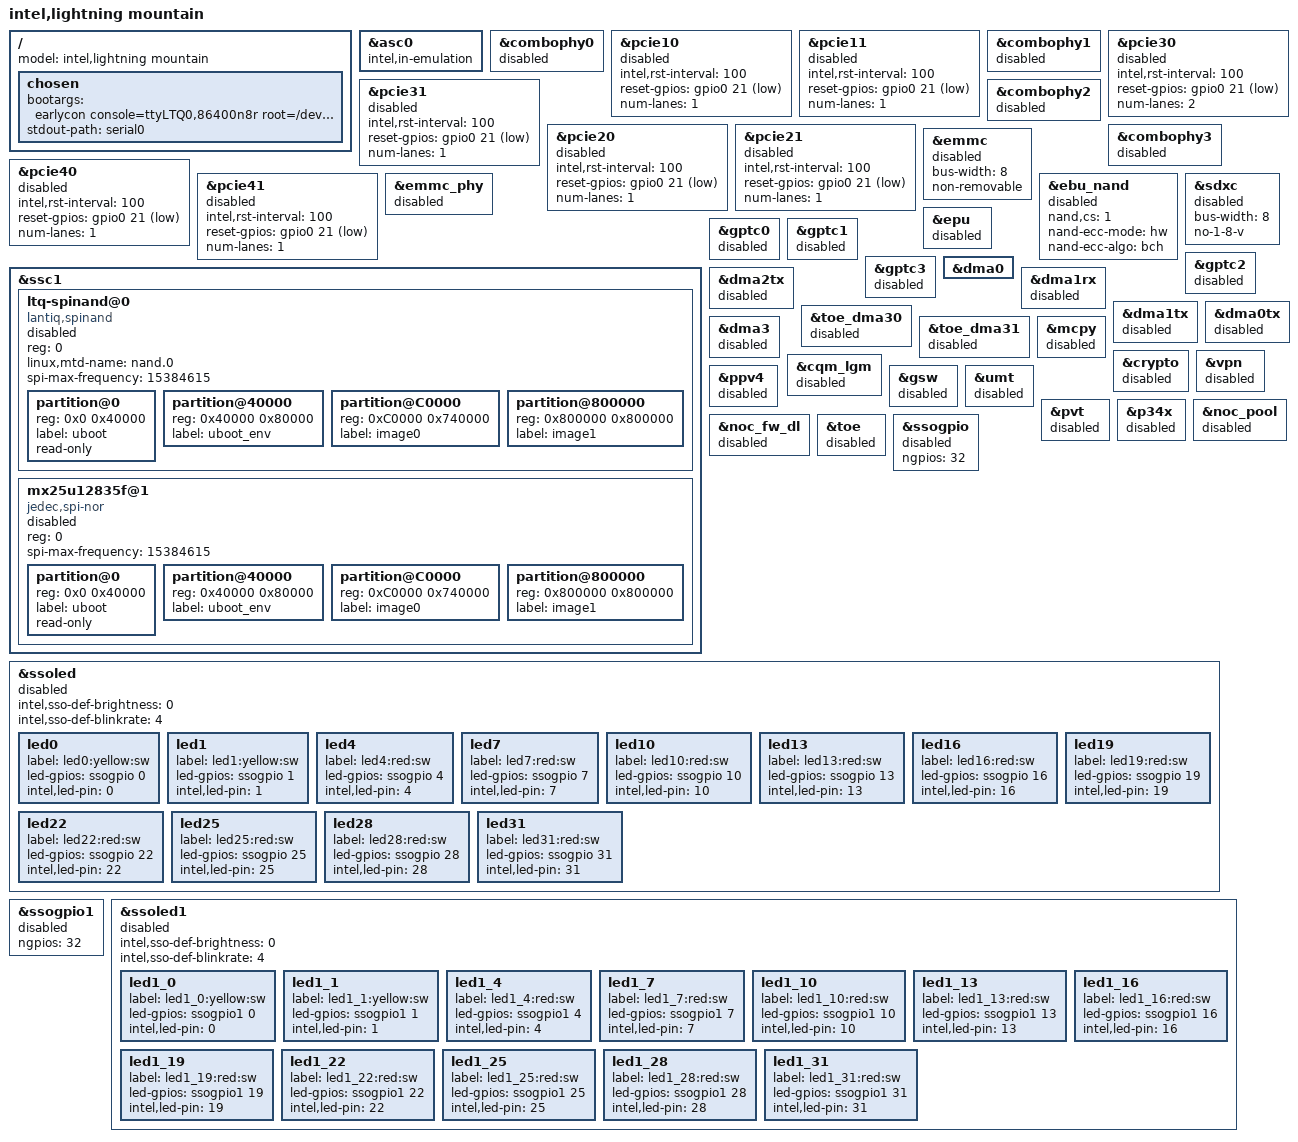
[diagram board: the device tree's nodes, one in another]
// SPDX-License-Identifier: GPL-2.0
/*
 * Copyright (c) 2018 Intel Corporation.
 */

/dts-v1/;
#include <dt-bindings/gpio/gpio.h>
#include <dt-bindings/clock/intel,lgm-clk.h>
#include <dt-bindings/interrupt-controller/irq.h>
#include "lightning_mountain_c.dtsi"

/ {
	model = "intel,lightning mountain";

	chosen {
		/* ramfs */
		bootargs = "earlycon console=ttyLTQ0,86400n8r root=/dev/ram init=/init maxcpus=4 initcall_debug=0 clk_ignore_unused loglevel=8";
		/* emmc squashfs */
		/* bootargs = "earlycon console=ttyLTQ1,115200n8r root=/dev/mmcblk0gp1 rootfstype=squashfs rootwait maxcpus=4 initcall_debug=0 clk_ignore_unused loglevel=8"; */

		stdout-path = "serial0";
	};
};

&asc0 {
	intel,in-emulation;
};

&combophy0 {
	status = "disabled";
};

&pcie10 {
	status = "disabled";
	intel,rst-interval = <100>;
	reset-gpios = <&gpio0 21 GPIO_ACTIVE_LOW>;
	num-lanes = <1>;
};

&pcie11 {
	status = "disabled";
	intel,rst-interval = <100>;
	reset-gpios = <&gpio0 21 GPIO_ACTIVE_LOW>;
	num-lanes = <1>;
};

&combophy1 {
	status = "disabled";
};

&pcie30 {
	status = "disabled";
	intel,rst-interval = <100>;
	reset-gpios = <&gpio0 21 GPIO_ACTIVE_LOW>;
	num-lanes = <2>;
};

&pcie31 {
	status = "disabled";
	intel,rst-interval = <100>;
	reset-gpios = <&gpio0 21 GPIO_ACTIVE_LOW>;
	num-lanes = <1>;
};

&combophy2 {
	status = "disabled";
};

&pcie20 {
	status = "disabled";
	intel,rst-interval = <100>;
	reset-gpios = <&gpio0 21 GPIO_ACTIVE_LOW>;
	num-lanes = <1>;
};

&pcie21 {
	status = "disabled";
	intel,rst-interval = <100>;
	reset-gpios = <&gpio0 21 GPIO_ACTIVE_LOW>;
	num-lanes = <1>;
};

&combophy3 {
	status = "disabled";
};

&pcie40 {
	status = "disabled";
	intel,rst-interval = <100>;
	reset-gpios = <&gpio0 21 GPIO_ACTIVE_LOW>;
	num-lanes = <1>;
};

&pcie41 {
	status = "disabled";
	intel,rst-interval = <100>;
	reset-gpios = <&gpio0 21 GPIO_ACTIVE_LOW>;
	num-lanes = <1>;
};

&emmc {
	bus-width = <8>;
	non-removable;
	status = "disabled";
};

&emmc_phy {
	status = "disabled";
};

&ebu_nand {
	status = "disabled";
	nand,cs = <1>;
	nand-ecc-mode = "hw";
	nand-ecc-algo = "bch";
	//pinctrl-names = "default";
	//pinctrl-0 = <&pinctrl_ebu_nand_base
	//	     &pinctrl_ebu_nand_ext
	//	     &pinctrl_ebu_nand_cs1>;

	/* epu is not available on haps */
	/delete-property/ power-domains;
};

&sdxc {
	bus-width = <8>;
	no-1-8-v;
	status = "disabled";
};

&ssc1 {
	ltq-spinand@0 {
		status = "disabled";
		#address-cells = <1>;
		#size-cells = <1>;
		reg = <0>;
		compatible = "lantiq,spinand";
		linux,mtd-name = "nand.0";
		spi-max-frequency = <15384615>;

		/* Basic fallback partition layout. Real partition should be
		 * defined in kernel boot parameters by uboot.
		 */
		partition@0 {
			reg = <0x0 0x40000>;
			label = "uboot";
			read-only;
		};

		partition@40000 {
			reg = <0x40000 0x80000>;
			label = "uboot_env";
		};

		partition@C0000 {
			reg = <0xC0000 0x740000>;
			label = "image0";
		};

		partition@800000 {
			reg = <0x800000 0x800000>;
			label = "image1";
		};
	};

	mx25u12835f@1 {
		status = "disabled";
		#address-cells = <1>;
		#size-cells = <1>;
		compatible = "jedec,spi-nor";
		reg = <0>;
		spi-max-frequency = <15384615>;

		/* Basic fallback partition layout. Real partition should be
		 * defined in kernel boot parameters by uboot.
		 */
		partition@0 {
			reg = <0x0 0x40000>;
			label = "uboot";
			read-only;
		};

		partition@40000 {
			reg = <0x40000 0x80000>;
			label = "uboot_env";
		};

		partition@C0000 {
			reg = <0xC0000 0x740000>;
			label = "image0";
		};

		partition@800000 {
			reg = <0x800000 0x800000>;
			label = "image1";
		};
	};
};

&epu {
	status = "disabled";
};

&gptc0 {
	status = "disabled";
};

&gptc1 {
	status = "disabled";
};

&gptc2 {
	status = "disabled";
};

&gptc3 {
	status = "disabled";
};

&dma0 {
	status = "okay";
};

&dma2tx {
	status = "disabled";
};

&dma1rx {
	status = "disabled";
};

&dma1tx {
	status = "disabled";
};

&dma0tx {
	status = "disabled";
};

&toe_dma30 {
	status = "disabled";
};

&toe_dma31 {
	status = "disabled";
};

&dma3 {
	status = "disabled";
};

&mcpy {
	status = "disabled";
};

&crypto {
	status = "disabled";
};

&vpn {
	status = "disabled";
};

&cqm_lgm {
	status = "disabled";
};

&ppv4 {
	status = "disabled";
};

&gsw {
	status = "disabled";
};

&umt {
	status = "disabled";
};

&pvt {
	status = "disabled";
};

&p34x {
	status = "disabled";
};

&noc_pool {
	status = "disabled";
};

&noc_fw_dl {
	status = "disabled";
};

&toe {
	status = "disabled";
};

/******************************************************************************
 ** Board configuration: Enable Shift register LED board configuration.
 ******************************************************************************/
&ssogpio {
	status = "disabled";
	ngpios = <32>;
};

&ssoled {
	status = "disabled";
	intel,sso-def-brightness = <0>;
	intel,sso-def-blinkrate = <4>;
	led0: led0 {
		label = "led0:yellow:sw";
		led-gpios = <&ssogpio 0 0>;
		intel,led-pin = <0>;
	};
	led1: led1 {
		label = "led1:yellow:sw";
		led-gpios = <&ssogpio 1 0>;
		intel,led-pin = <1>;
	};
	led4: led4 {
		label = "led4:red:sw";
		led-gpios = <&ssogpio 4 0>;
		intel,led-pin = <4>;
	};
	led7: led7 {
		label = "led7:red:sw";
		led-gpios = <&ssogpio 7 0>;
		intel,led-pin = <7>;
	};
	led10: led10 {
		label = "led10:red:sw";
		led-gpios = <&ssogpio 10 0>;
		intel,led-pin = <10>;
	};
	led13: led13 {
		label = "led13:red:sw";
		led-gpios = <&ssogpio 13 0>;
		intel,led-pin = <13>;
	};
	led16: led16 {
		label = "led16:red:sw";
		led-gpios = <&ssogpio 16 0>;
		intel,led-pin = <16>;
	};
	led19: led19 {
		label = "led19:red:sw";
		led-gpios = <&ssogpio 19 0>;
		intel,led-pin = <19>;
	};
	led22: led22 {
		label = "led22:red:sw";
		led-gpios = <&ssogpio 22 0>;
		intel,led-pin = <22>;
	};
	led25: led25 {
		label = "led25:red:sw";
		led-gpios = <&ssogpio 25 0>;
		intel,led-pin = <25>;
	};
	led28: led28 {
		label = "led28:red:sw";
		led-gpios = <&ssogpio 28 0>;
		intel,led-pin = <28>;
	};
	led31: led31 {
		label = "led31:red:sw";
		led-gpios = <&ssogpio 31 0>;
		intel,led-pin = <31>;
	};

};

&ssogpio1 {
	status = "disabled";
	ngpios = <32>;
};

&ssoled1 {
	status = "disabled";
	/* led definition */
	intel,sso-def-brightness = <0>; /* default off */
	intel,sso-def-blinkrate = <4>; /* HZ*/
	/* blink rate list: 2, 4, 8, 10, 50K, 100K, 200K, 250K, 1000K */
	led1_0: led1_0 {
		label = "led1_0:yellow:sw";
		led-gpios = <&ssogpio1 0 0>;
		intel,led-pin = <0>;
	};
	led1_1: led1_1 {
		label = "led1_1:yellow:sw";
		led-gpios = <&ssogpio1 1 0>;
		intel,led-pin = <1>;
	};
	led1_4: led1_4 {
		label = "led1_4:red:sw";
		led-gpios = <&ssogpio1 4 0>;
		intel,led-pin = <4>;
	};
	led1_7: led1_7 {
		label = "led1_7:red:sw";
		led-gpios = <&ssogpio1 7 0>;
		intel,led-pin = <7>;
	};
	led1_10: led1_10 {
		label = "led1_10:red:sw";
		led-gpios = <&ssogpio1 10 0>;
		intel,led-pin = <10>;
	};
	led1_13: led1_13 {
		label = "led1_13:red:sw";
		led-gpios = <&ssogpio1 13 0>;
		intel,led-pin = <13>;
	};
	led1_16: led1_16 {
		label = "led1_16:red:sw";
		led-gpios = <&ssogpio1 16 0>;
		intel,led-pin = <16>;
	};
	led1_19: led1_19 {
		label = "led1_19:red:sw";
		led-gpios = <&ssogpio1 19 0>;
		intel,led-pin = <19>;
	};
	led1_22: led1_22 {
		label = "led1_22:red:sw";
		led-gpios = <&ssogpio1 22 0>;
		intel,led-pin = <22>;
	};
	led1_25: led1_25 {
		label = "led1_25:red:sw";
		led-gpios = <&ssogpio1 25 0>;
		intel,led-pin = <25>;
	};
	led1_28: led1_28 {
		label = "led1_28:red:sw";
		led-gpios = <&ssogpio1 28 0>;
		intel,led-pin = <28>;
	};
	led1_31: led1_31 {
		label = "led1_31:red:sw";
		led-gpios = <&ssogpio1 31 0>;
		intel,led-pin = <31>;
	};
};
